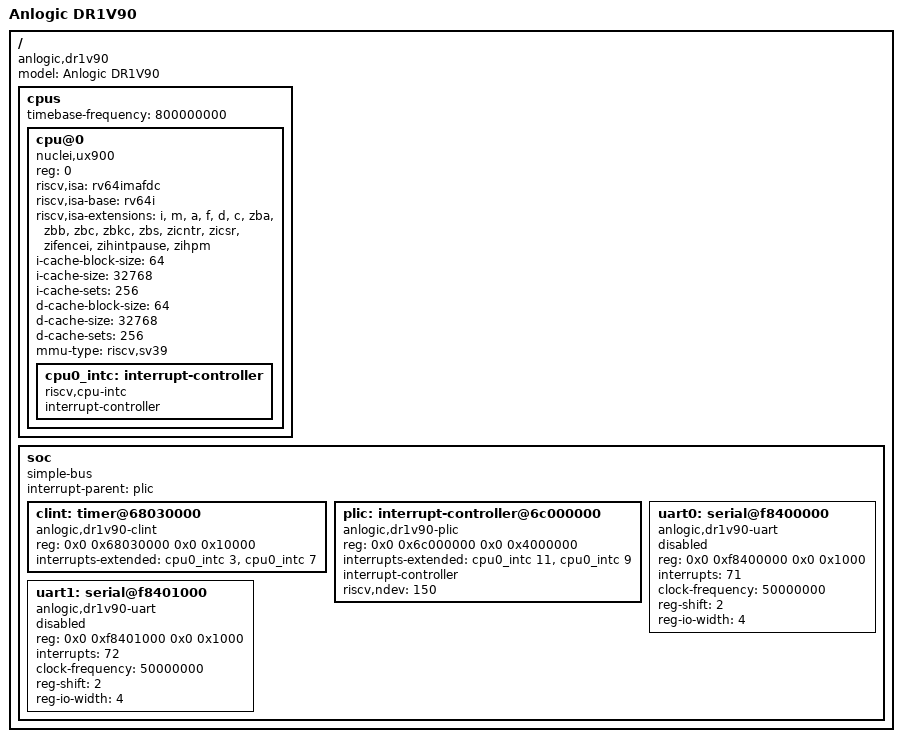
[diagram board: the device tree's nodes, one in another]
// SPDX-License-Identifier: GPL-2.0 OR MIT
/*
 * Copyright (C) 2025 Junhui Liu <junhui.liu@pigmoral.tech>
 */

/dts-v1/;
/ {
	#address-cells = <2>;
	#size-cells = <2>;
	model = "Anlogic DR1V90";
	compatible = "anlogic,dr1v90";

	cpus {
		#address-cells = <1>;
		#size-cells = <0>;
		timebase-frequency = <800000000>;

		cpu@0 {
			compatible = "nuclei,ux900", "riscv";
			device_type = "cpu";
			reg = <0>;
			riscv,isa = "rv64imafdc";
			riscv,isa-base = "rv64i";
			riscv,isa-extensions = "i", "m", "a", "f", "d", "c", "zba", "zbb", "zbc",
					       "zbkc", "zbs", "zicntr", "zicsr", "zifencei",
					       "zihintpause", "zihpm";
			i-cache-block-size = <64>;
			i-cache-size = <32768>;
			i-cache-sets = <256>;
			d-cache-block-size = <64>;
			d-cache-size = <32768>;
			d-cache-sets = <256>;
			mmu-type = "riscv,sv39";

			cpu0_intc: interrupt-controller {
				compatible = "riscv,cpu-intc";
				interrupt-controller;
				#interrupt-cells = <1>;
			};
		};
	};

	soc {
		compatible = "simple-bus";
		interrupt-parent = <&plic>;
		#address-cells = <2>;
		#size-cells = <2>;
		ranges;

		clint: timer@68030000 {
			compatible = "anlogic,dr1v90-clint", "sifive,clint0";
			reg = <0x0 0x68030000 0x0 0x10000>;
			interrupts-extended = <&cpu0_intc 3>, <&cpu0_intc 7>;
		};

		plic: interrupt-controller@6c000000 {
			compatible = "anlogic,dr1v90-plic", "sifive,plic-1.0.0";
			reg = <0x0 0x6c000000 0x0 0x4000000>;
			interrupts-extended = <&cpu0_intc 11>, <&cpu0_intc 9>;
			interrupt-controller;
			#address-cells = <0>;
			#interrupt-cells = <1>;
			riscv,ndev = <150>;
		};

		uart0: serial@f8400000 {
			compatible = "anlogic,dr1v90-uart", "snps,dw-apb-uart";
			reg = <0x0 0xf8400000 0x0 0x1000>;
			interrupts = <71>;
			clock-frequency = <50000000>;
			reg-shift = <2>;
			reg-io-width = <4>;
			status = "disabled";
		};

		uart1: serial@f8401000 {
			compatible = "anlogic,dr1v90-uart", "snps,dw-apb-uart";
			reg = <0x0 0xf8401000 0x0 0x1000>;
			interrupts = <72>;
			clock-frequency = <50000000>;
			reg-shift = <2>;
			reg-io-width = <4>;
			status = "disabled";
		};
	};
};
